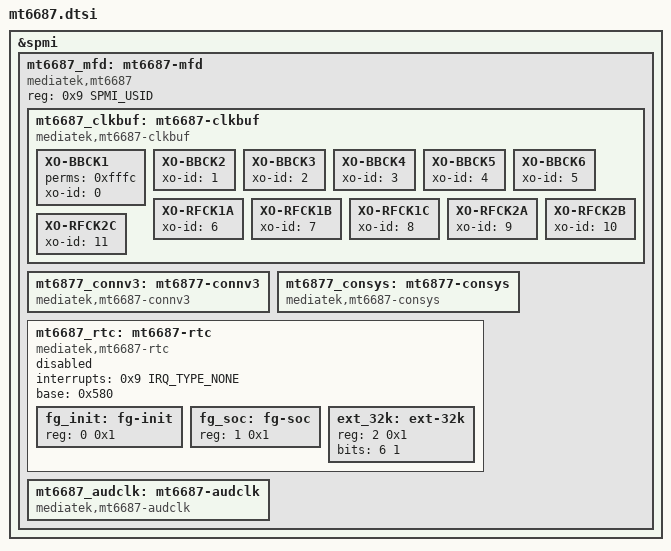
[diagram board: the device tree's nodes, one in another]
// SPDX-License-Identifier: GPL-2.0-only OR BSD-2-Clause
/*
 * Copyright (c) 2024 MediaTek Inc.
 */
#include <dt-bindings/spmi/spmi.h>

&spmi {
	mt6687_mfd: mt6687-mfd {
		compatible = "mediatek,mt6687";
		reg = <0x9 SPMI_USID>;
		mt6687_clkbuf: mt6687-clkbuf {
			compatible = "mediatek,mt6687-clkbuf";
			XO-BBCK1 {
				perms = <0xfffc>;
				xo-id = <0>;
			};
			XO-BBCK2 {
				xo-id = <1>;
			};
			XO-BBCK3 {
				xo-id = <2>;
			};
			XO-BBCK4 {
				xo-id = <3>;
			};
			XO-BBCK5 {
				xo-id = <4>;
			};
			XO-BBCK6 {
				xo-id = <5>;
			};
			XO-RFCK1A {
				xo-id = <6>;
			};
			XO-RFCK1B {
				xo-id = <7>;
			};
			XO-RFCK1C {
				xo-id = <8>;
			};
			XO-RFCK2A {
				xo-id = <9>;
			};
			XO-RFCK2B {
				xo-id = <10>;
			};
			XO-RFCK2C {
				xo-id = <11>;
			};
		};

		mt6877_connv3: mt6877-connv3 {
			compatible = "mediatek,mt6687-connv3";
		};

		mt6877_consys: mt6877-consys {
			compatible = "mediatek,mt6687-consys";
		};

		mt6687_rtc: mt6687-rtc {
			status = "disabled";
			compatible = "mediatek,mt6687-rtc";
			interrupts = <0x9 IRQ_TYPE_NONE>;
			interrupt-names = "rtc";
			base = <0x580>;

			#address-cells = <1>;
			#size-cells = <1>;

			fg_init: fg-init {
				reg = <0 0x1>;
			};
			fg_soc: fg-soc {
				reg = <1 0x1>;
			};
			ext_32k: ext-32k {
				reg = <2 0x1>;
				bits = <6 1>;
			};
		};

		mt6687_audclk: mt6687-audclk {
			compatible = "mediatek,mt6687-audclk";
		};
	};
};
